# STM32H7R3xx register map
File version: 1.0
Registers are 32-bit, read-write, reset 0x0 unless marked. A register's access mark holds for its fields unless they carry their own. Offsets are from the block's base; [hi:lo] are bit positions; {n}, {i} and the like mark numbered series; 'fields as' and 'values as' point back to an identical list.

## CRC — CRC calculation unit
Base 0x58024C00
0x00 DR — CRC Data register
  [31:0] DR — Data register bits
0x04 IDR — CRC Independent data register
  [31:0] IDR — General-purpose 32-bits data register bits
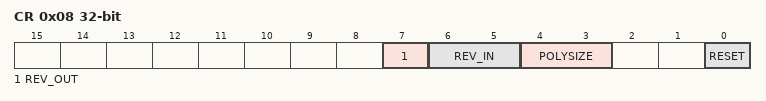
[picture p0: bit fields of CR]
0x08 CR — CRC Control register
  [7] REV_OUT — REV_OUT Reverse Output Data bits
    0=NONE (Output Data bit order not affected); 1=BIT (Output Data bit reversal done by bit)
  [6:5] REV_IN — REV_IN Reverse Input Data bits
    0=NONE (Input Data bit order not affected); 1=BYTE (Input Data bit reversal done by byte); 2=HALFWORD (Input Data bit reversal done by half-word); 3=WORD (Input Data bit reversal done by word)
  [4:3] POLYSIZE — Polynomial size bits
    0=POLYLENGTH_32B (32 bits Polynomial size); 1=POLYLENGTH_16B (16 bits Polynomial size); 2=POLYLENGTH_8B (8 bits Polynomial size); 3=POLYLENGTH_7B (7 bits Polynomial size)
  [0] RESET — RESET the CRC computation unit bit
0x10 INIT — Initial CRC value register
  [31:0] INIT — Initial CRC value bits
0x14 POL — CRC polynomial register
  [31:0] POL — Coefficients of the polynomial

## DBGMCU — Debug MCU
Base 0x5C001000
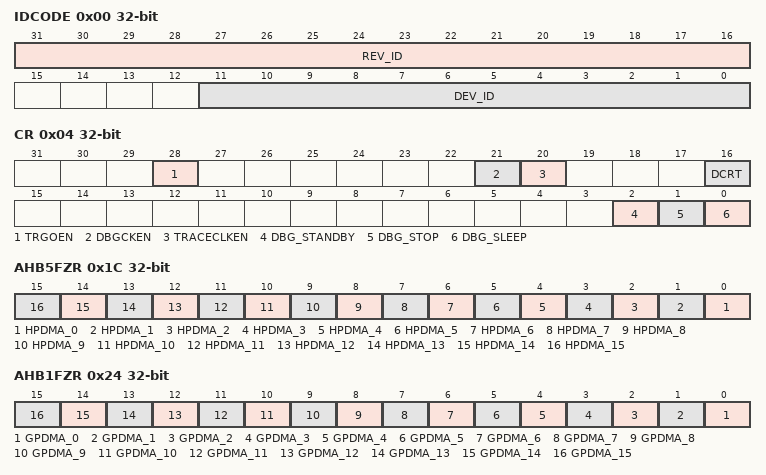
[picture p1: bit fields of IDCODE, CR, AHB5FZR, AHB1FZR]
0x00 IDCODE — MCU device ID code
  [31:16] REV_ID — Revision
  [11:0] DEV_ID — Device ID
0x04 CR — Debug MCU configuration register
  [28] TRGOEN — External trigger output enable
  [21] DBGCKEN — Debug clock enable
  [20] TRACECLKEN — Trace port clock enable
  [16] DCRT — Debug credentials reset type
    0=SYSTEM (System reset revoke the debug authentication credentials); 1=POWER (Power reset revoke the debug authentication credentials)
  [2] DBG_STANDBY — Debug in Standby mode enable
  [1] DBG_STOP — Debug in Stop mode enable
  [0] DBG_SLEEP — Debug in Sleep mode enable
0x1C AHB5FZR — Debug MCU AHB5FZR freeze register
  [n] HPDMA_{n} (n=0..15) — HPDMA channel {n} stop in debug
0x24 AHB1FZR — Debug MCU AHB1FZR freeze register
  [n] GPDMA_{n} (n=0..15) — GPDMA channel {n} stop in debug
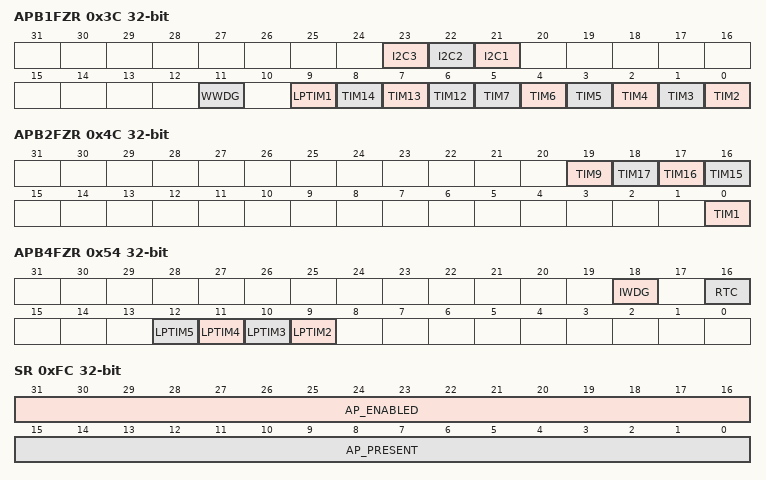
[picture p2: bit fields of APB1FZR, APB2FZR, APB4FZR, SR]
0x3C APB1FZR — Debug MCU APB1FZR freeze register
  [23] I2C3 — I2C3 SMBUS timeout stop in debug
  [22] I2C2 — I2C2 SMBUS timeout stop in debug
  [21] I2C1 — I2C1 SMBUS timeout stop in debug
  [11] WWDG — WWDG stop in debug
  [9] LPTIM1 — LPTIM1 stop in debug
  [8] TIM14 — TIM14 stop in debug
  [7] TIM13 — TIM13 stop in debug
  [6] TIM12 — TIM12 stop in debug
  [n-2] TIM{n} (n=2..7) — TIM{n} stop in debug
0x4C APB2FZR — Debug MCU APB2FZR freeze register
  [19] TIM9 — TIM9 stop in debug
  [18] TIM17 — TIM17 stop in debug
  [17] TIM16 — TIM16 stop in debug
  [16] TIM15 — TIM15 stop in debug
  [0] TIM1 — TIM1 stop in debug
0x54 APB4FZR — Debug MCU APB4FZR freeze register
  [18] IWDG — Independent watchdog for stop in debug
  [16] RTC — RTC stop in debug
  [n+7] LPTIM{n} (n=2..5) — LPTIM{n} stop in debug
0xFC SR — Debug MCU status register
  [31:16] AP_ENABLED, [15:0] AP_PRESENT
0x100 DBG_AUTH_HOST — Debug MCU Authentication Host register
  [31:0] MESSAGE — Debug host to device mailbox message
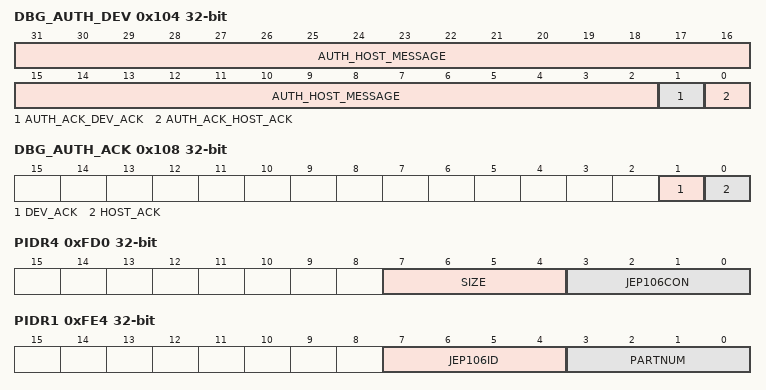
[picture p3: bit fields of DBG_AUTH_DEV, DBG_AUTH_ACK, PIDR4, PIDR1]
0x104 DBG_AUTH_DEV — Debug MCU Authentication Device register
  [31:2] AUTH_HOST_MESSAGE — Debug host to device mailbox message
  [1] AUTH_ACK_DEV_ACK — Device to host acknowledge
  [0] AUTH_ACK_HOST_ACK — Host to device acknowledge
0x108 DBG_AUTH_ACK — Debug MCU Authentication Ack register
  [1] DEV_ACK — Device to host acknowledge
  [0] HOST_ACK — Host to device acknowledge
0xFD0 PIDR4 — Debug MCU peripheral identity register 4
  [7:4] SIZE — Register file size
  [3:0] JEP106CON — JEP106 continuation code
0xFE0 PIDR0 — Debug MCU peripheral identity register 0
  [7:0] PARTNUM — Part number field, bits [7:0]
0xFE4 PIDR1 — Debug MCU peripheral identity register 1
  [7:4] JEP106ID — JEP106 identity code field, bits [3:0]
  [3:0] PARTNUM — Part number field, bits [11:8]
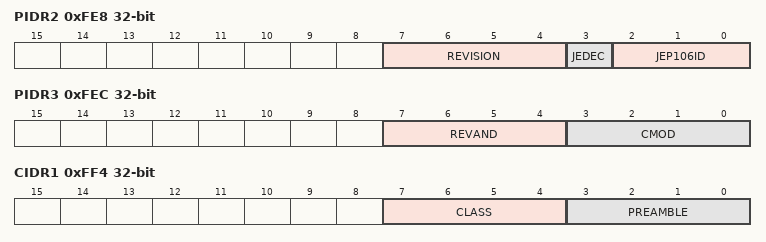
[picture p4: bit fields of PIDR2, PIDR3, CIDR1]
0xFE8 PIDR2 — Debug MCU peripheral identity register 2
  [7:4] REVISION — Component revision number
  [3] JEDEC — JEDEC assigned value
  [2:0] JEP106ID — JEP106 identity code field, bits [6:4]
0xFEC PIDR3 — Debug MCU peripheral identity register 3
  [7:4] REVAND — Metal fix version
  [3:0] CMOD — Customer modified
0xFF0 CIDR0 — Debug MCU component identity register 0
  [7:0] PREAMBLE — Component ID field, bits [7:0]
0xFF4 CIDR1 — Debug MCU component identity register 1
  [7:4] CLASS — Component ID field, bits [15:12] - component class
  [3:0] PREAMBLE — Component ID field, bits [11:8]
0xFF8 CIDR2 — Debug MCU component identity register 2
  [7:0] PREAMBLE — Component ID field, bits [23:16]
0xFFC CIDR3 — Debug MCU component identity register 3
  [7:0] PREAMBLE — Component ID field, bits [31:24]

## AXIM_AMIB_1
Base 0xBFF02000
Same registers: AXIM_AMIB_{n} {0xBFF01000+0x1000*n} (n=2..10)
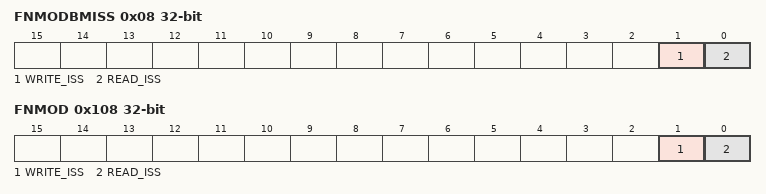
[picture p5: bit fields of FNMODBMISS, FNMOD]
0x08 FNMODBMISS — AXIM AMIB fn_mod_bm_iss register
  [1] WRITE_ISS — Force write issuing capability to 1
  [0] READ_ISS — Force read issuing capability to 1
0x24 FNMOD2 — AXIM AMIB fn_mod2 register
  [0] BYPASS_MERGE — Bypass Merge enable
0x2C FNMODLB — AXIM AMIB fn_mod_lb register
  [0] LONG_BURST — Long bursts can be generated
0x108 FNMOD — AXIM AMIB fn_mod register
  fields as FNMODBMISS

## AXIM_ASIB_1 — AXIM ASIB
Base 0xBFF42000
Same registers: AXIM_ASIB_{n} {0xBFF41000+0x1000*n} (n=2..11)
0x24 FNMOD2 — AXIM ASIB fn_mod2 register
  [0] BYPASS_MERGE — Bypass Merge enable
0x100 READQOS — AXIM ASIB read_qos register
  [3:0] AR_QOS — Read channel QoS setting
0x104 WRITEQOS — AXIM ASIB write_qos register
  [3:0] AW_QOS — Write channel QoS setting
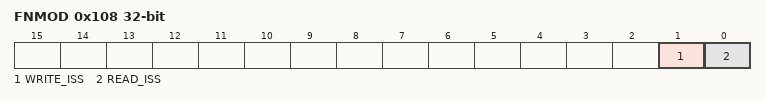
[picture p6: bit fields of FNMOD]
0x108 FNMOD — AXIM ASIB fn_mod register
  [1] WRITE_ISS — Force write issuing capability to 1
  [0] READ_ISS — Force read issuing capability to 1
